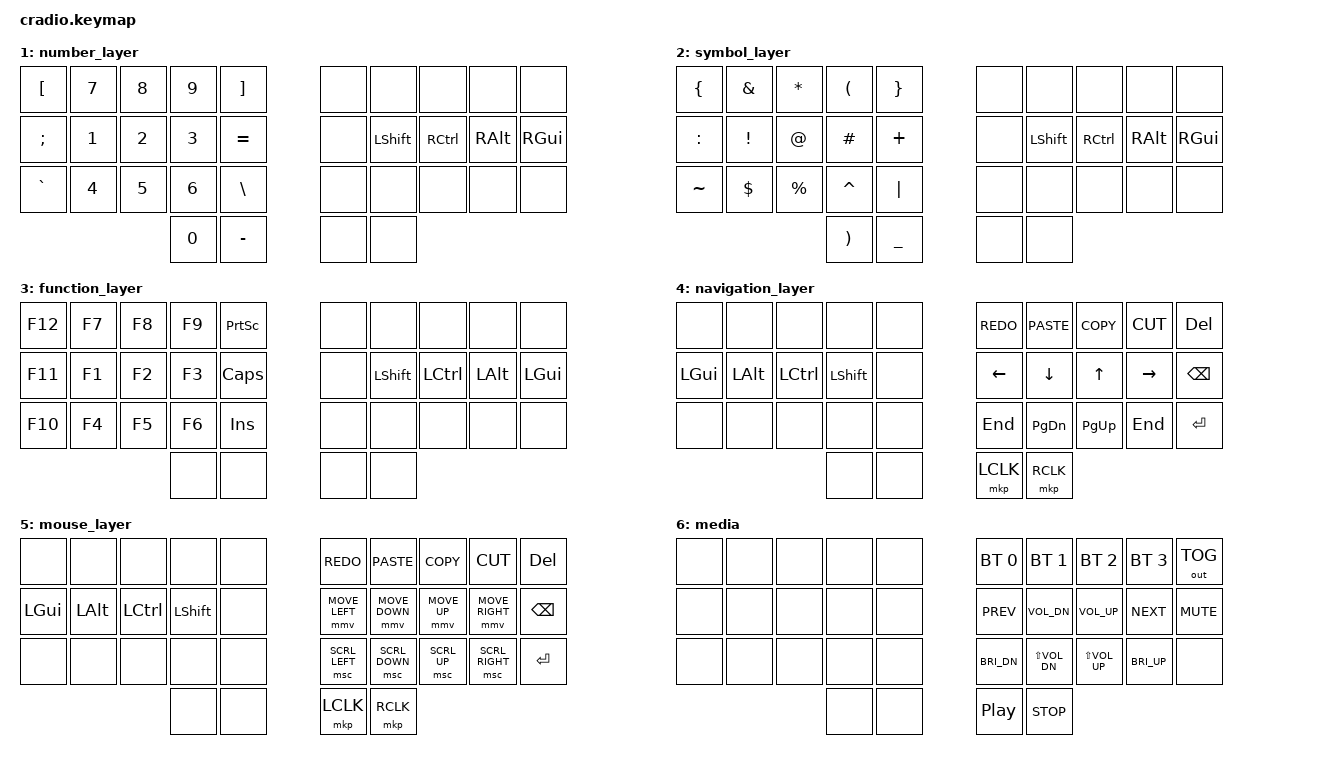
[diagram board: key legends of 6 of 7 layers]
// need to put this before include pointing
#define ZMK_POINTING_DEFAULT_MOVE_VAL 800
#define ZMK_POINTING_DEFAULT_SCRL_VAL 10

#include <behaviors.dtsi>
#include <dt-bindings/zmk/keys.h>
#include <dt-bindings/zmk/bt.h>
#include <dt-bindings/zmk/outputs.h>
#include <dt-bindings/zmk/pointing.h>

// Define layers
#define NUM 1
#define SYM 2
#define FUN 3
#define NAV 4
#define MOUSE 5
#define MEDIA 6

// Home row mods macro
#define HRML(k1,k2,k3,k4) &hml LGUI k1  &hml LALT k2  &hml LCTRL k3  &hml LSHFT k4
#define HRMR(k1,k2,k3,k4) &hmr LSHFT k1  &hmr LCTRL k2  &hmr LALT k3  &hmr LGUI k4

#define ht_tt 190
#define ht_qt 125
#define ht_rpi 90

//#define ht_tt 280
//#define ht_qt 175
//#define ht_rpi 150
/ {
    behaviors {
        lt: layer_tap {
            compatible = "zmk,behavior-hold-tap";
            #binding-cells = <2>;
            flavor = "tap-preferred";
            tapping-term-ms = <ht_tt>;
            bindings = <&mo>, <&kp>;
            quick-tap-ms = <ht_qt>;
        };

        hml: home_row_mod_left {
            compatible = "zmk,behavior-hold-tap";
            #binding-cells = <2>;
            flavor = "tap-preferred";
            require-prior-idle-ms = <ht_rpi>;
            tapping-term-ms = <ht_tt>;
            quick-tap-ms = <ht_qt>;
            bindings = <&kp>, <&kp>;
            hold-trigger-on-release;
        };
        hmr: home_row_mod_right {
            compatible = "zmk,behavior-hold-tap";
            #binding-cells = <2>;
            flavor = "tap-preferred";
            require-prior-idle-ms = <ht_rpi>;
            tapping-term-ms = <ht_tt>;
            quick-tap-ms = <ht_qt>;
            bindings = <&kp>, <&kp>;
            hold-trigger-on-release;
        };
        //I used for prior version of mod tap
        ht: hold_tap {
            compatible = "zmk,behavior-hold-tap";
            #binding-cells = <2>;
            flavor = "tap-preferred";
            tapping-term-ms = <ht_tt>;
            quick-tap-ms = <ht_qt>;
            require-prior-idle-ms = <ht_rpi>;
            bindings = <&kp>, <&kp>;
        };
    };
    combos {
        compatible = "zmk,combos";
        combo_esc {
            timeout-ms = <60>;
            key-positions = <31 32>;
            bindings = <&kp ESC>;
            layers = <0>;
            require-prior-idle-ms = <100>;
        };
        combo_capword{
            timeout-ms = <60>;
            key-positions = <30 33>;
            bindings = <&caps_word>;
            layers = <0>;
            require-prior-idle-ms = <100>;
        };
        combo_bluetooth_clear{
            timeout-ms = <40>;
            key-positions = <2 7>;
            bindings = <&bt BT_CLR>;
            layers = <6>;
            require-prior-idle-ms = <100>;
        };
        combo_bootloader{
            timeout-ms = <40>;
            key-positions = <0 9>;
            bindings = <&bootloader>;
            layers = <6>;
            require-prior-idle-ms = <100>;
        };
    };

    keymap {
        compatible = "zmk,keymap";
        default_layer {
            bindings = <
                //╭──────────┬──────────┬──────────┬──────────┬──────────╮   ╭──────────┬──────────┬──────────┬──────────┬──────────╮
                //│    Q     │    W     │    F     │    P     │    B     │   │    J     │    L     │    U     │    Y     │    '     │
                    &kp Q      &kp W      &kp F      &kp P      &kp B          &kp J      &kp L     &kp U        &kp Y      &kp SQT
                //├──────────┼──────────┼──────────┼──────────┼──────────┤   ├──────────┼──────────┼──────────┼──────────┼──────────┤
                //│    A     │    R     │    S     │    T     │    G     │   │    M     │    N     │    E     │    I     │    O     │
                    HRML( A,     R,        S,           T)      &lt MEDIA G   &lt FUN M  HRMR(N,      E,        I,         O)
                //├──────────┼──────────┼──────────┼──────────┼──────────┤   ├──────────┼──────────┼──────────┼──────────┼──────────┤
                //│    Z     │    X     │    C     │    D     │    V     │   │    K     │    H     │ , <      │ . >      │ / ?      │
                    &kp Z       &kp X      &kp C      &kp D      &kp V         &kp K      &kp H      &kp COMMA  &kp DOT    &kp FSLH
                //╰──────────┴──────────┴──────────┼──────────┼──────────┤   ├──────────┼──────────┼──────────┴──────────┴──────────╯
                                                   &lt NAV TAB &lt MOUSE BSPC  &lt SYM SPACE &lt NUM ENTER
                //                                 ╰──────────┴──────────╯   ╰──────────┴──────────╯
            >;
        };

        number_layer {
            bindings = <
                //╭──────────┬──────────┬──────────┬──────────┬──────────╮   ╭──────────┬──────────┬──────────┬──────────┬──────────╮
                //│    [     │    7     │    8     │    9     │    ]     │   │          │          │          │          │          │
                    &kp LBKT    &kp N7     &kp N8     &kp N9    &kp RBKT        &none      &none      &none      &none      &none
                //├──────────┼──────────┼──────────┼──────────┼──────────┤   ├──────────┼──────────┼──────────┼──────────┼──────────┤
                //│    ;     │    1     │    2     │    3     │    =     │   │          │          │          │          │          │
                    &kp SEMI    &kp N1     &kp N2     &kp N3    &kp EQUAL       &none    &kp LSHIFT  &kp RCTRL  &kp RALT   &kp RGUI
                //├──────────┼──────────┼──────────┼──────────┼──────────┤   ├──────────┼──────────┼──────────┼──────────┼──────────┤
                //│     `    │    4     │    5     │    6     │    \     │   │          │          │          │          │          │
                    &kp GRAVE   &kp N4     &kp N5     &kp N6    &kp BSLH        &none      &none      &none      &none      &none
                //╰──────────┴──────────┴──────────┼──────────┼──────────┤   ├──────────┼──────────┼──────────┴──────────┴──────────╯
                                                     &kp N0     &kp MINUS       &none       &none
                //                                 ╰──────────┴──────────╯   ╰──────────┴──────────╯
            >;
        };

        symbol_layer {
            bindings = <
                //╭──────────┬──────────┬──────────┬──────────┬──────────╮   ╭──────────┬──────────┬──────────┬──────────┬──────────╮
                //│     {    │    @     │    #     │    )     │    }     │   │          │          │          │          │          │
                    &kp LBRC   &kp AMPS   &kp ASTRK  &kp LPAR   &kp RBRC        &none      &none      &none      &none      &none
                //├──────────┼──────────┼──────────┼──────────┼──────────┤   ├──────────┼──────────┼──────────┼──────────┼──────────┤
                //│    :     │    !     │    @     │    #     │    +     │   │          │          │          │          │          │
                   &kp COLON   &kp EXCL    &kp AT   &kp HASH    &kp PLUS        &none    &kp LSHIFT  &kp RCTRL  &kp RALT   &kp RGUI
                //├──────────┼──────────┼──────────┼──────────┼──────────┤   ├──────────┼──────────┼──────────┼──────────┼──────────┤
                //│    ~     │    $     │    %     │    ^     │    |     │   │          │          │          │          │          │
                   &kp TILDE   &kp DLLR   &kp PRCNT  &kp CARET  &kp PIPE       &none      &none      &none      &none      &none
                //╰──────────┴──────────┴──────────┼──────────┼──────────┤   ├──────────┼──────────┼──────────┴──────────┴──────────╯
                                                     &kp RPAR   &kp UNDER       &none       &none
                //                                 ╰──────────┴──────────╯   ╰──────────┴──────────╯
            >;
        };
        function_layer {
            bindings = <
                //╭──────────┬──────────┬──────────┬──────────┬──────────╮   ╭──────────┬──────────┬──────────┬──────────┬──────────╮
                //│   F12    │   F7     │   F8     │   F9     │          │   │          │          │          │          │          │
                    &kp F12     &kp F7     &kp F8     &kp F9    &kp PSCRN      &none      &none      &none      &none      &none
                //├──────────┼──────────┼──────────┼──────────┼──────────┤   ├──────────┼──────────┼──────────┼──────────┼──────────┤
                //│   F11    │   F1     │   F2     │   F3     │          │   │          │          │          │          │          │
                    &kp F11     &kp F1     &kp F2     &kp F3  &kp CAPS       &none    &kp LSHIFT  &kp LCTRL  &kp LALT   &kp LGUI
                //├──────────┼──────────┼──────────┼──────────┼──────────┤   ├──────────┼──────────┼──────────┼──────────┼──────────┤
                //│   F10    │   F4     │   F5     │   F6     │          │   │          │          │          │          │          │
                    &kp F10     &kp F4     &kp F5     &kp F6     &kp INS         &none      &none      &none      &none      &none
                //╰──────────┴──────────┴──────────┼──────────┼──────────┤   ├──────────┼──────────┼──────────┴──────────┴──────────╯
                                                     &none      &none           &none       &none
                //                                 ╰──────────┴──────────╯   ╰──────────┴──────────╯
            >;
        };
        navigation_layer {
            bindings = <
                //╭──────────┬──────────┬──────────┬──────────┬──────────╮   ╭──────────┬──────────┬──────────┬──────────┬──────────╮
                //│          │          │          │          │          │   │          │          │          │          │          │
                    &none       &none      &none      &none     &none          &kp K_REDO &kp K_PASTE &kp K_COPY &kp K_CUT &kp DEL
                //├──────────┼──────────┼──────────┼──────────┼──────────┤   ├──────────┼──────────┼──────────┼──────────┼──────────┤
                //│          │          │          │          │          │   │   left   │  down    │   up     │  right   │          │
                    &kp LGUI   &kp LALT   &kp LCTRL  &kp LSHFT  &none          &kp LEFT   &kp DOWN   &kp UP     &kp RIGHT  &kp BSPC
                //├──────────┼──────────┼──────────┼──────────┼──────────┤   ├──────────┼──────────┼──────────┼──────────┼──────────┤
                //│          │          │          │          │          │   │          │          │          │          │          │
                    &none       &none      &none      &none     &none          &kp END    &kp PG_DN  &kp PG_UP   &kp END   &kp ENTER
                //╰──────────┴──────────┴──────────┼──────────┼──────────┤   ├──────────┼──────────┼──────────┴──────────┴──────────╯
                                                      &none       &none        &mkp LCLK  &mkp RCLK
            //                                     ╰──────────┴──────────╯   ╰──────────┴──────────╯
            >;
        };
        mouse_layer{
            bindings = <
                //╭──────────┬──────────┬──────────┬──────────┬──────────╮   ╭──────────┬──────────┬──────────┬──────────┬──────────╮
                //│          │          │          │          │          │   │          │          │          │          │          │
                    &none       &none      &none      &none     &none          &kp K_REDO &kp K_PASTE &kp K_COPY &kp K_CUT  &kp DEL
                //├──────────┼──────────┼──────────┼──────────┼──────────┤   ├──────────┼──────────┼──────────┼──────────┼──────────┤
                //│          │          │          │          │          │   │   left   │   down   │    up    │  right   │          │
                    &kp LGUI   &kp LALT   &kp LCTRL  &kp LSHFT   &none   &mmv MOVE_LEFT &mmv MOVE_DOWN &mmv MOVE_UP &mmv MOVE_RIGHT  &kp BSPC
                //├──────────┼──────────┼──────────┼──────────┼──────────┤   ├──────────┼──────────┼──────────┼──────────┼──────────┤
                //│          │          │          │          │          │   │ m left   │ m down   │  m up    │ m  right │          │
                     &none      &none      &none      &none       &none  &msc SCRL_LEFT &msc SCRL_DOWN &msc SCRL_UP &msc SCRL_RIGHT &kp ENTER
                //╰──────────┴──────────┴──────────┼──────────┼──────────┤   ├──────────┼──────────┼──────────┴──────────┴──────────╯
                                                      &none       &none        &mkp LCLK  &mkp RCLK
            //                                     ╰──────────┴──────────╯   ╰──────────┴──────────╯
            >;
        };

        media {
            bindings = <
                //╭──────────┬──────────┬──────────┬──────────┬──────────╮   ╭──────────┬──────────┬──────────┬──────────┬──────────╮
                //│          │          │          │          │          │   │          │          │          │          │          │
                    &none       &none      &none      &none     &none    &bt BT_SEL 0 &bt BT_SEL 1 &bt BT_SEL 2 &bt BT_SEL 3  &out OUT_TOG
                //├──────────┼──────────┼──────────┼──────────┼──────────┤   ├──────────┼──────────┼──────────┼──────────┼──────────┤
                //│          │          │          │          │          │   │          │          │          │          │          │
                     &none      &none     &none       &none      &none       &kp C_PREV &kp C_VOL_DN &kp C_VOL_UP &kp C_NEXT &kp C_MUTE
                //├──────────┼──────────┼──────────┼──────────┼──────────┤   ├──────────┼──────────┼──────────┼──────────┼──────────┤
                //│          │          │          │          │          │   │          │          │          │          │          │
                    &none       &none      &none      &none      &none      &kp C_BRI_DN  &kp LS(C_VOL_DN) &kp LS(C_VOL_UP) &kp C_BRI_UP &none
                //╰──────────┴──────────┴──────────┼──────────┼──────────┤   ├──────────┼──────────┼──────────┴──────────┴──────────╯
                                                     &none      &none          &kp C_PP    &kp C_STOP
                //                                 ╰──────────┴──────────╯   ╰──────────┴──────────╯
            >;
        };
    };
};
